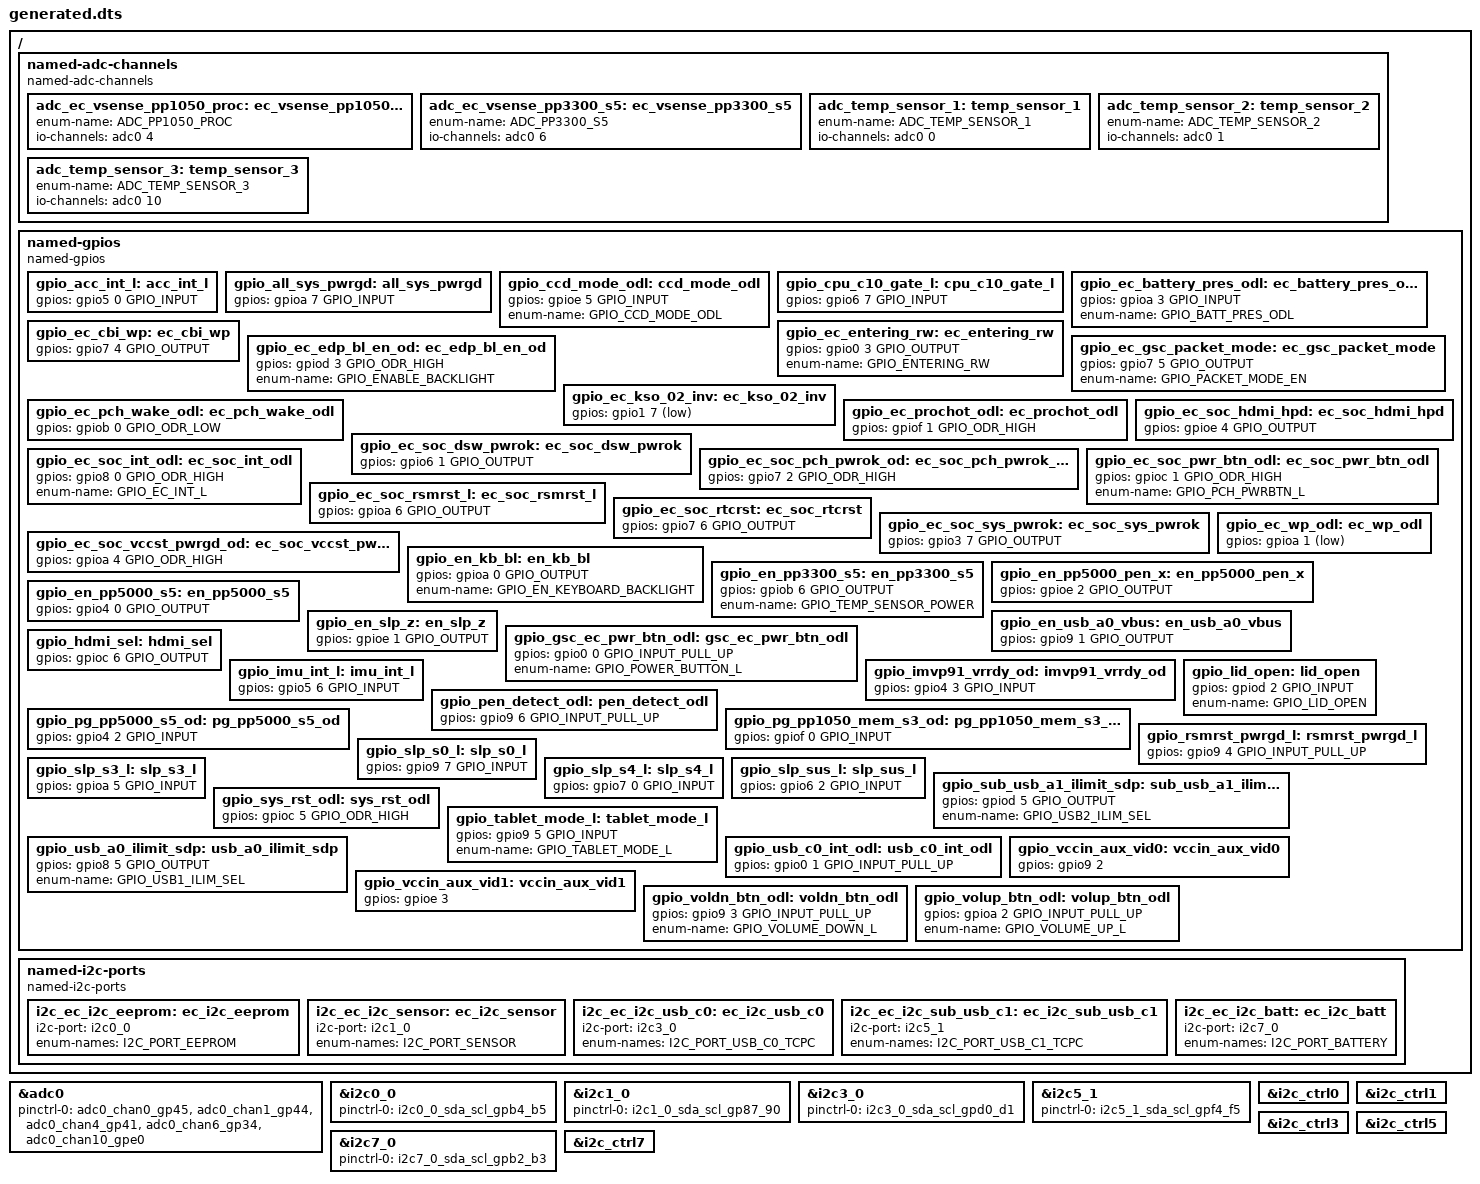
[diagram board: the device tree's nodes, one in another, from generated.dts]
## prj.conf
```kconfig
# Copyright 2022 The ChromiumOS Authors
# Use of this source code is governed by a BSD-style license that can be
# found in the LICENSE file.

CONFIG_BOARD_CRAASK=y
CONFIG_PLATFORM_EC_OCPC=y

# Sensor drivers
CONFIG_PLATFORM_EC_ACCELGYRO_LSM6DSO=y
CONFIG_PLATFORM_EC_ACCEL_BMA4XX=y
CONFIG_PLATFORM_EC_ACCELGYRO_BMI_COMM_I2C=y
CONFIG_PLATFORM_EC_ACCELGYRO_BMI3XX=y
CONFIG_PLATFORM_EC_DYNAMIC_MOTION_SENSOR_COUNT=y

CONFIG_PLATFORM_EC_BUTTONS_RUNTIME_CONFIG=y
```

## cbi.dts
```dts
/* Copyright 2022 The ChromiumOS Authors
 * Use of this source code is governed by a BSD-style license that can be
 * found in the LICENSE file.
 */

/ {
	/* Craask-specific fw_config fields. */
	nissa-fw-config {
		/*
		 * FW_CONFIG field to describe Lid sensor orientation.
		 */
		lid-inversion {
			enum-name = "FW_LID_INVERSION";
			start = <8>;
			size = <1>;

			/*
			 * 0: regular placement of the lid sensor
			 * 1: rotate 180' of xy plane.
			 */
			regular {
				compatible = "cros-ec,cbi-fw-config-value";
				enum-name = "FW_LID_REGULAR";
				value = <0>;
				default;
			};
			xy_rotate_180 {
				compatible = "cros-ec,cbi-fw-config-value";
				enum-name = "FW_LID_XY_ROT_180";
				value = <1>;
			};
		};
	};
	/* Craask-specific ssfc fields. */
	cbi-ssfc {
		compatible = "named-cbi-ssfc";
		/*
		 * SSFC bit0-1 was defined for AUDIO CODEC.
		 * 0: ALC5682I_VS
		 * 1: NAU8825
		 */
		audio_codec {
			enum-name = "AUDIO_CODEC";
			size = <2>;
		};
		/*
		 * SSFC field to identify LID motion sensor.
		 */
		lid-sensor {
			enum-name = "LID_SENSOR";
			size = <2>;

			lid_sensor_0: lis2dw12 {
				compatible = "named-cbi-ssfc-value";
				status = "okay";
				value = <0>;
				default;
			};
			lid_sensor_1: bma422 {
				compatible = "named-cbi-ssfc-value";
				status = "okay";
				value = <1>;
			};
		};
		/*
		 * SSFC field to identify BASE motion sensor.
		 */
		base-sensor {
			enum-name = "BASE_SENSOR";
			size = <2>;

			base_sensor_0: lsm6dso {
				compatible = "named-cbi-ssfc-value";
				status = "okay";
				value = <0>;
				default;
			};
			base_sensor_1: bmi323 {
				compatible = "named-cbi-ssfc-value";
				status = "okay";
				value = <1>;
			};
		};
	};
};
```

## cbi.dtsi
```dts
/* Copyright 2022 The ChromiumOS Authors
 * Use of this source code is governed by a BSD-style license that can be
 * found in the LICENSE file.
 */

/ {
	/* Craask-specific fw_config fields. */
	nissa-fw-config {
		/*
		 * FW_CONFIG field to describe Lid sensor orientation.
		 */
		lid-inversion {
			enum-name = "FW_LID_INVERSION";
			start = <8>;
			size = <1>;

			/*
			 * 0: regular placement of the lid sensor
			 * 1: rotate 180' of xy plane.
			 */
			regular {
				compatible = "cros-ec,cbi-fw-config-value";
				enum-name = "FW_LID_REGULAR";
				value = <0>;
				default;
			};
			xy_rotate_180 {
				compatible = "cros-ec,cbi-fw-config-value";
				enum-name = "FW_LID_XY_ROT_180";
				value = <1>;
			};
		};
		/*
		 * FW_CONFIG field to describe Clamshell/Convertible.
		 */
		form_factor {
			enum-name = "FORM_FACTOR";
			start = <9>;
			size = <1>;

			/*
			 * 0: convertible, 1: clamshell
			 */
			convertible {
				compatible = "cros-ec,cbi-fw-config-value";
				enum-name = "CONVERTIBLE";
				value = <0>;
			};
			clamshell {
				compatible = "cros-ec,cbi-fw-config-value";
				enum-name = "CLAMSHELL";
				value = <1>;
			};
		};
	};
	/* Craask-specific ssfc fields. */
	cbi-ssfc {
		compatible = "named-cbi-ssfc";
		/*
		 * SSFC bit0-1 was defined for AUDIO CODEC.
		 * 0: ALC5682I_VS
		 * 1: NAU8825
		 */
		audio_codec {
			enum-name = "AUDIO_CODEC";
			size = <2>;
		};
		/*
		 * SSFC field to identify LID motion sensor.
		 */
		lid-sensor {
			enum-name = "LID_SENSOR";
			size = <2>;

			lid_sensor_0: lis2dw12 {
				compatible = "named-cbi-ssfc-value";
				status = "okay";
				value = <0>;
				default;
			};
			lid_sensor_1: bma422 {
				compatible = "named-cbi-ssfc-value";
				status = "okay";
				value = <1>;
			};
		};
		/*
		 * SSFC field to identify BASE motion sensor.
		 */
		base-sensor {
			enum-name = "BASE_SENSOR";
			size = <2>;

			base_sensor_0: lsm6dso {
				compatible = "named-cbi-ssfc-value";
				status = "okay";
				value = <0>;
				default;
			};
			base_sensor_1: bmi323 {
				compatible = "named-cbi-ssfc-value";
				status = "okay";
				value = <1>;
			};
		};
	};
};
```

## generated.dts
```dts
/* Copyright 2022 The ChromiumOS Authors
 * Use of this source code is governed by a BSD-style license that can be
 * found in the LICENSE file.
 */

/ {

	named-adc-channels {
		compatible = "named-adc-channels";

		adc_ec_vsense_pp1050_proc: ec_vsense_pp1050_proc {
			enum-name = "ADC_PP1050_PROC";
			io-channels = <&adc0 4>;
		};
		adc_ec_vsense_pp3300_s5: ec_vsense_pp3300_s5 {
			enum-name = "ADC_PP3300_S5";
			io-channels = <&adc0 6>;
		};
		adc_temp_sensor_1: temp_sensor_1 {
			enum-name = "ADC_TEMP_SENSOR_1";
			io-channels = <&adc0 0>;
		};
		adc_temp_sensor_2: temp_sensor_2 {
			enum-name = "ADC_TEMP_SENSOR_2";
			io-channels = <&adc0 1>;
		};
		adc_temp_sensor_3: temp_sensor_3 {
			enum-name = "ADC_TEMP_SENSOR_3";
			io-channels = <&adc0 10>;
		};
	};

	named-gpios {
		compatible = "named-gpios";

		gpio_acc_int_l: acc_int_l {
			gpios = <&gpio5 0 GPIO_INPUT>;
		};
		gpio_all_sys_pwrgd: all_sys_pwrgd {
			gpios = <&gpioa 7 GPIO_INPUT>;
		};
		gpio_ccd_mode_odl: ccd_mode_odl {
			gpios = <&gpioe 5 GPIO_INPUT>;
			enum-name = "GPIO_CCD_MODE_ODL";
		};
		gpio_cpu_c10_gate_l: cpu_c10_gate_l {
			gpios = <&gpio6 7 GPIO_INPUT>;
		};
		gpio_ec_battery_pres_odl: ec_battery_pres_odl {
			gpios = <&gpioa 3 GPIO_INPUT>;
			enum-name = "GPIO_BATT_PRES_ODL";
		};
		gpio_ec_cbi_wp: ec_cbi_wp {
			gpios = <&gpio7 4 GPIO_OUTPUT>;
		};
		gpio_ec_edp_bl_en_od: ec_edp_bl_en_od {
			gpios = <&gpiod 3 GPIO_ODR_HIGH>;
			enum-name = "GPIO_ENABLE_BACKLIGHT";
		};
		gpio_ec_entering_rw: ec_entering_rw {
			gpios = <&gpio0 3 GPIO_OUTPUT>;
			enum-name = "GPIO_ENTERING_RW";
		};
		gpio_ec_gsc_packet_mode: ec_gsc_packet_mode {
			gpios = <&gpio7 5 GPIO_OUTPUT>;
			enum-name = "GPIO_PACKET_MODE_EN";
		};
		gpio_ec_kso_02_inv: ec_kso_02_inv {
			gpios = <&gpio1 7 (GPIO_OUTPUT | GPIO_ACTIVE_LOW)>;
		};
		gpio_ec_pch_wake_odl: ec_pch_wake_odl {
			gpios = <&gpiob 0 GPIO_ODR_LOW>;
		};
		gpio_ec_prochot_odl: ec_prochot_odl {
			gpios = <&gpiof 1 GPIO_ODR_HIGH>;
		};
		gpio_ec_soc_dsw_pwrok: ec_soc_dsw_pwrok {
			gpios = <&gpio6 1 GPIO_OUTPUT>;
		};
		gpio_ec_soc_hdmi_hpd: ec_soc_hdmi_hpd {
			gpios = <&gpioe 4 GPIO_OUTPUT>;
		};
		gpio_ec_soc_int_odl: ec_soc_int_odl {
			gpios = <&gpio8 0 GPIO_ODR_HIGH>;
			enum-name = "GPIO_EC_INT_L";
		};
		gpio_ec_soc_pch_pwrok_od: ec_soc_pch_pwrok_od {
			gpios = <&gpio7 2 GPIO_ODR_HIGH>;
		};
		gpio_ec_soc_pwr_btn_odl: ec_soc_pwr_btn_odl {
			gpios = <&gpioc 1 GPIO_ODR_HIGH>;
			enum-name = "GPIO_PCH_PWRBTN_L";
		};
		gpio_ec_soc_rsmrst_l: ec_soc_rsmrst_l {
			gpios = <&gpioa 6 GPIO_OUTPUT>;
		};
		gpio_ec_soc_rtcrst: ec_soc_rtcrst {
			gpios = <&gpio7 6 GPIO_OUTPUT>;
		};
		gpio_ec_soc_sys_pwrok: ec_soc_sys_pwrok {
			gpios = <&gpio3 7 GPIO_OUTPUT>;
		};
		gpio_ec_soc_vccst_pwrgd_od: ec_soc_vccst_pwrgd_od {
			gpios = <&gpioa 4 GPIO_ODR_HIGH>;
		};
		gpio_ec_wp_odl: ec_wp_odl {
			gpios = <&gpioa 1 (GPIO_INPUT | GPIO_ACTIVE_LOW)>;
		};
		gpio_en_kb_bl: en_kb_bl {
			gpios = <&gpioa 0 GPIO_OUTPUT>;
			enum-name = "GPIO_EN_KEYBOARD_BACKLIGHT";
		};
		gpio_en_pp3300_s5: en_pp3300_s5 {
			gpios = <&gpiob 6 GPIO_OUTPUT>;
			enum-name = "GPIO_TEMP_SENSOR_POWER";
		};
		gpio_en_pp5000_pen_x: en_pp5000_pen_x {
			gpios = <&gpioe 2 GPIO_OUTPUT>;
		};
		gpio_en_pp5000_s5: en_pp5000_s5 {
			gpios = <&gpio4 0 GPIO_OUTPUT>;
		};
		gpio_en_slp_z: en_slp_z {
			gpios = <&gpioe 1 GPIO_OUTPUT>;
		};
		gpio_en_usb_a0_vbus: en_usb_a0_vbus {
			gpios = <&gpio9 1 GPIO_OUTPUT>;
		};
		gpio_gsc_ec_pwr_btn_odl: gsc_ec_pwr_btn_odl {
			gpios = <&gpio0 0 GPIO_INPUT_PULL_UP>;
			enum-name = "GPIO_POWER_BUTTON_L";
		};
		gpio_hdmi_sel: hdmi_sel {
			gpios = <&gpioc 6 GPIO_OUTPUT>;
		};
		gpio_imu_int_l: imu_int_l {
			gpios = <&gpio5 6 GPIO_INPUT>;
		};
		gpio_imvp91_vrrdy_od: imvp91_vrrdy_od {
			gpios = <&gpio4 3 GPIO_INPUT>;
		};
		gpio_lid_open: lid_open {
			gpios = <&gpiod 2 GPIO_INPUT>;
			enum-name = "GPIO_LID_OPEN";
		};
		gpio_pen_detect_odl: pen_detect_odl {
			gpios = <&gpio9 6 GPIO_INPUT_PULL_UP>;
		};
		gpio_pg_pp1050_mem_s3_od: pg_pp1050_mem_s3_od {
			gpios = <&gpiof 0 GPIO_INPUT>;
		};
		gpio_pg_pp5000_s5_od: pg_pp5000_s5_od {
			gpios = <&gpio4 2 GPIO_INPUT>;
		};
		gpio_rsmrst_pwrgd_l: rsmrst_pwrgd_l {
			gpios = <&gpio9 4 GPIO_INPUT_PULL_UP>;
		};
		gpio_slp_s0_l: slp_s0_l {
			gpios = <&gpio9 7 GPIO_INPUT>;
		};
		gpio_slp_s3_l: slp_s3_l {
			gpios = <&gpioa 5 GPIO_INPUT>;
		};
		gpio_slp_s4_l: slp_s4_l {
			gpios = <&gpio7 0 GPIO_INPUT>;
		};
		gpio_slp_sus_l: slp_sus_l {
			gpios = <&gpio6 2 GPIO_INPUT>;
		};
		gpio_sub_usb_a1_ilimit_sdp: sub_usb_a1_ilimit_sdp {
			gpios = <&gpiod 5 GPIO_OUTPUT>;
			enum-name = "GPIO_USB2_ILIM_SEL";
		};
		gpio_sys_rst_odl: sys_rst_odl {
			gpios = <&gpioc 5 GPIO_ODR_HIGH>;
		};
		gpio_tablet_mode_l: tablet_mode_l {
			gpios = <&gpio9 5 GPIO_INPUT>;
			enum-name = "GPIO_TABLET_MODE_L";
		};
		gpio_usb_a0_ilimit_sdp: usb_a0_ilimit_sdp {
			gpios = <&gpio8 5 GPIO_OUTPUT>;
			enum-name = "GPIO_USB1_ILIM_SEL";
		};
		gpio_usb_c0_int_odl: usb_c0_int_odl {
			gpios = <&gpio0 1 GPIO_INPUT_PULL_UP>;
		};
		gpio_vccin_aux_vid0: vccin_aux_vid0 {
			gpios = <&gpio9 2 (GPIO_INPUT | GPIO_VOLTAGE_1P8)>;
		};
		gpio_vccin_aux_vid1: vccin_aux_vid1 {
			gpios = <&gpioe 3 (GPIO_INPUT | GPIO_VOLTAGE_1P8)>;
		};
		gpio_voldn_btn_odl: voldn_btn_odl {
			gpios = <&gpio9 3 GPIO_INPUT_PULL_UP>;
			enum-name = "GPIO_VOLUME_DOWN_L";
		};
		gpio_volup_btn_odl: volup_btn_odl {
			gpios = <&gpioa 2 GPIO_INPUT_PULL_UP>;
			enum-name = "GPIO_VOLUME_UP_L";
		};
	};

	named-i2c-ports {
		compatible = "named-i2c-ports";

		i2c_ec_i2c_eeprom: ec_i2c_eeprom {
			i2c-port = <&i2c0_0>;
			enum-names = "I2C_PORT_EEPROM";
		};
		i2c_ec_i2c_sensor: ec_i2c_sensor {
			i2c-port = <&i2c1_0>;
			enum-names = "I2C_PORT_SENSOR";
		};
		i2c_ec_i2c_usb_c0: ec_i2c_usb_c0 {
			i2c-port = <&i2c3_0>;
			enum-names = "I2C_PORT_USB_C0_TCPC";
		};
		i2c_ec_i2c_sub_usb_c1: ec_i2c_sub_usb_c1 {
			i2c-port = <&i2c5_1>;
			enum-names = "I2C_PORT_USB_C1_TCPC";
		};
		i2c_ec_i2c_batt: ec_i2c_batt {
			i2c-port = <&i2c7_0>;
			enum-names = "I2C_PORT_BATTERY";
		};
	};
};

&adc0 {
	status = "okay";
	pinctrl-0 = <&adc0_chan0_gp45
		     &adc0_chan1_gp44
		     &adc0_chan4_gp41
		     &adc0_chan6_gp34
		     &adc0_chan10_gpe0>;
	pinctrl-names = "default";
};

&i2c0_0 {
	status = "okay";
	pinctrl-0 = <&i2c0_0_sda_scl_gpb4_b5>;
	pinctrl-names = "default";
};

&i2c1_0 {
	status = "okay";
	pinctrl-0 = <&i2c1_0_sda_scl_gp87_90>;
	pinctrl-names = "default";
};

&i2c3_0 {
	status = "okay";
	pinctrl-0 = <&i2c3_0_sda_scl_gpd0_d1>;
	pinctrl-names = "default";
};

&i2c5_1 {
	status = "okay";
	pinctrl-0 = <&i2c5_1_sda_scl_gpf4_f5>;
	pinctrl-names = "default";
};

&i2c7_0 {
	status = "okay";
	pinctrl-0 = <&i2c7_0_sda_scl_gpb2_b3>;
	pinctrl-names = "default";
};

&i2c_ctrl0 {
	status = "okay";
};

&i2c_ctrl1 {
	status = "okay";
};

&i2c_ctrl3 {
	status = "okay";
};

&i2c_ctrl5 {
	status = "okay";
};

&i2c_ctrl7 {
	status = "okay";
};
```

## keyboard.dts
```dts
/* Copyright 2022 The Chromium OS Authors. All rights reserved.
 * Use of this source code is governed by a BSD-style license that can be
 * found in the LICENSE file.
 */

&cros_kb_raw {
	status = "okay";
	/* No KSO2 (it's inverted and implemented by GPIO) */
	pinctrl-0 = <
		&ksi0_gp31
		&ksi1_gp30
		&ksi2_gp27
		&ksi3_gp26
		&ksi4_gp25
		&ksi5_gp24
		&ksi6_gp23
		&ksi7_gp22
		&kso00_gp21
		&kso01_gp20
		&kso03_gp16
		&kso04_gp15
		&kso05_gp14
		&kso06_gp13
		&kso07_gp12
		&kso08_gp11
		&kso09_gp10
		&kso10_gp07
		&kso11_gp06
		&kso12_gp05
	>;
	pinctrl-names = "default";
};
```

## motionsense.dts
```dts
/* Copyright 2022 The Chromium OS Authors. All rights reserved.
 * Use of this source code is governed by a BSD-style license that can be
 * found in the LICENSE file.
 */

#include <dt-bindings/motionsense/utils.h>


/ {
	aliases {
		/*
		 * Interrupt bindings for sensor devices.
		 */
		lsm6dso-int = &base_accel;
		lis2dw12-int = &lid_accel;
		bmi3xx-int = &base_accel;
	};

	/*
	 * Declare mutexes used by sensor drivers.
	 * A mutex node is used to create an instance of mutex_t.
	 * A mutex node is referenced by a sensor node if the
	 * corresponding sensor driver needs to use the
	 * instance of the mutex.
	 */
	motionsense-mutex {
		compatible = "cros-ec,motionsense-mutex";
		lid_mutex: lis2dw12-mutex {
		};

		lid_mutex_bma422: bma422-mutex {
		};

		base_mutex: base-mutex {
		};

		base_mutex_bmi323: bmi323-mutex {
		};
	};

	/* Rotation matrix used by drivers. */
	motionsense-rotation-ref {
		compatible = "cros-ec,motionsense-rotation-ref";
		lid_rot_ref: lid-rotation-ref {
			mat33 = <(-1) 0 0
				 0 1 0
				 0 0 (-1)>;
		};

		base_rot_ref: base-rotation-ref {
			mat33 = <1 0 0
				 0 (-1) 0
				 0 0 (-1)>;
		};

		base_rot_ver1: base-rotation-ver1 {
			mat33 = <(-1) 0 0
				 0 (-1) 0
				 0 0 1>;
		};

		lid_rot_bma422: lid-rotation-bma {
			mat33 = <1 0 0
				 0 (-1) 0
				 0 0 (-1)>;
		};

		base_rot_bmi323: base-rotation-bmi323 {
			mat33 = <1 0 0
				 0 (-1) 0
				 0 0 (-1)>;
		};
	};

	/*
	 * Driver specific data. A driver-specific data can be shared with
	 * different motion sensors while they are using the same driver.
	 *
	 * If a node's compatible starts with "cros-ec,accelgyro-", it is for
	 * a common structure defined in accelgyro.h.
	 * e.g) compatible = "cros-ec,accelgyro-als-drv-data" is for
	 * "struct als_drv_data_t" in accelgyro.h
	 */
	motionsense-sensor-data {
		lsm6dso_accel_data: lsm6dso-accel-drv-data {
			compatible = "cros-ec,drvdata-lsm6dso";
			status = "okay";
		};

		lsm6dso_gyro_data: lsm6dso-gyro-drv-data {
			compatible = "cros-ec,drvdata-lsm6dso";
			status = "okay";
		};

		lis2dw12_data: lis2dw12-drv-data {
			compatible = "cros-ec,drvdata-lis2dw12";
			status = "okay";
		};

		bma422_data: bma4xx-drv-data {
			compatible = "cros-ec,drvdata-bma4xx";
			status = "okay";
		};

		bmi323_data: bmi323-drv-data {
			compatible = "cros-ec,drvdata-bmi3xx";
			status = "okay";
		};
	};

	/*
	 * List of motion sensors that creates motion_sensors array.
	 * The nodelabel "lid_accel" and "base_accel" are used to indicate
	 * motion sensor IDs for lid angle calculation.
	 * TODO(b/238139272): The first entries of the array must be
	 * accelerometers,then gyroscope. Fix this dependency in the DTS
	 * processing which makes the devicetree entries independent.
	 */
	motionsense-sensor {
		lid_accel: lid-accel {
			compatible = "cros-ec,lis2dw12";
			status = "okay";

			active-mask = "SENSOR_ACTIVE_S0_S3";
			location = "MOTIONSENSE_LOC_LID";
			mutex = <&lid_mutex>;
			port = <&i2c_ec_i2c_sensor>;
			rot-standard-ref = <&lid_rot_ref>;
			default-range = <2>;
			drv-data = <&lis2dw12_data>;
			i2c-spi-addr-flags = "LIS2DWL_ADDR0_FLAGS";
			configs {
				compatible =
					"cros-ec,motionsense-sensor-config";
				ec-s0 {
					odr = <(10000 | ROUND_UP_FLAG)>;
				};
				ec-s3 {
					odr = <(10000 | ROUND_UP_FLAG)>;
				};
			};
		};

		base_accel: base-accel {
			compatible = "cros-ec,lsm6dso-accel";
			status = "okay";

			active-mask = "SENSOR_ACTIVE_S0_S3";
			location = "MOTIONSENSE_LOC_BASE";
			mutex = <&base_mutex>;
			port = <&i2c_ec_i2c_sensor>;
			rot-standard-ref = <&base_rot_ref>;
			drv-data = <&lsm6dso_accel_data>;
			configs {
				compatible =
					"cros-ec,motionsense-sensor-config";
				ec-s0 {
					odr = <(10000 | ROUND_UP_FLAG)>;
				};
				ec-s3 {
					odr = <(10000 | ROUND_UP_FLAG)>;
				};
			};
		};

		base_gyro: base-gyro {
			compatible = "cros-ec,lsm6dso-gyro";
			status = "okay";

			active-mask = "SENSOR_ACTIVE_S0_S3";
			location = "MOTIONSENSE_LOC_BASE";
			mutex = <&base_mutex>;
			port = <&i2c_ec_i2c_sensor>;
			rot-standard-ref = <&base_rot_ref>;
			default-range = <(1000 | ROUND_UP_FLAG)>; /* dps */
			drv-data = <&lsm6dso_gyro_data>;
		};
	};

	motionsense-sensor-alt {
		alt_lid_accel: alt-lid-accel {
			compatible = "cros-ec,bma4xx";
			status = "okay";

			active-mask = "SENSOR_ACTIVE_S0_S3";
			location = "MOTIONSENSE_LOC_LID";
			mutex = <&lid_mutex_bma422>;
			port = <&i2c_ec_i2c_sensor>;
			rot-standard-ref = <&lid_rot_bma422>;
			default-range = <2>;
			drv-data = <&bma422_data>;
			i2c-spi-addr-flags = "BMA4_I2C_ADDR_PRIMARY";
			alternate-for = <&lid_accel>;
			alternate-ssfc-indicator = <&lid_sensor_1>;
			configs {
				compatible =
					"cros-ec,motionsense-sensor-config";
				ec-s0 {
					odr = <(10000 | ROUND_UP_FLAG)>;
				};
				ec-s3 {
					odr = <(10000 | ROUND_UP_FLAG)>;
				};
			};
		};

		alt_base_accel: alt-base-accel {
			compatible = "cros-ec,bmi3xx-accel";
			status = "okay";

			active-mask = "SENSOR_ACTIVE_S0_S3";
			location = "MOTIONSENSE_LOC_BASE";
			mutex = <&base_mutex_bmi323>;
			port = <&i2c_ec_i2c_sensor>;
			rot-standard-ref = <&base_rot_bmi323>;
			drv-data = <&bmi323_data>;
			alternate-for = <&base_accel>;
			alternate-ssfc-indicator = <&base_sensor_1>;
			configs {
				compatible =
					"cros-ec,motionsense-sensor-config";
				ec-s0 {
					odr = <(10000 | ROUND_UP_FLAG)>;
				};
				ec-s3 {
					odr = <(10000 | ROUND_UP_FLAG)>;
				};
			};
		};

		alt_base_gyro: alt-base-gyro {
			compatible = "cros-ec,bmi3xx-gyro";
			status = "okay";

			active-mask = "SENSOR_ACTIVE_S0_S3";
			location = "MOTIONSENSE_LOC_BASE";
			mutex = <&base_mutex_bmi323>;
			port = <&i2c_ec_i2c_sensor>;
			rot-standard-ref = <&base_rot_bmi323>;
			drv-data = <&bmi323_data>;
			alternate-for = <&base_gyro>;
			alternate-ssfc-indicator = <&base_sensor_1>;
		};
	};

	motionsense-sensor-info {
		compatible = "cros-ec,motionsense-sensor-info";

		/*
		 * list of GPIO interrupts that have to
		 * be enabled at initial stage
		 */
		sensor-irqs = <&int_imu>;
		/* list of sensors in force mode */
		accel-force-mode-sensors = <&lid_accel>;
	};
};
```

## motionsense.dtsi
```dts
/* Copyright 2022 The ChromiumOS Authors
 * Use of this source code is governed by a BSD-style license that can be
 * found in the LICENSE file.
 */

#include <dt-bindings/motionsense/utils.h>


/ {
	aliases {
		/*
		 * Interrupt bindings for sensor devices.
		 */
		lsm6dso-int = &base_accel;
		lis2dw12-int = &lid_accel;
		bmi3xx-int = &base_accel;
	};

	/*
	 * Declare mutexes used by sensor drivers.
	 * A mutex node is used to create an instance of mutex_t.
	 * A mutex node is referenced by a sensor node if the
	 * corresponding sensor driver needs to use the
	 * instance of the mutex.
	 */
	motionsense-mutex {
		compatible = "cros-ec,motionsense-mutex";
		lid_mutex: lis2dw12-mutex {
		};

		lid_mutex_bma422: bma422-mutex {
		};

		base_mutex: base-mutex {
		};

		base_mutex_bmi323: bmi323-mutex {
		};
	};

	/* Rotation matrix used by drivers. */
	motionsense-rotation-ref {
		compatible = "cros-ec,motionsense-rotation-ref";
		lid_rot_ref: lid-rotation-ref {
			mat33 = <(-1) 0 0
				 0 1 0
				 0 0 (-1)>;
		};

		base_rot_ref: base-rotation-ref {
			mat33 = <1 0 0
				 0 (-1) 0
				 0 0 (-1)>;
		};

		base_rot_ver1: base-rotation-ver1 {
			mat33 = <(-1) 0 0
				 0 (-1) 0
				 0 0 1>;
		};

		lid_rot_bma422: lid-rotation-bma {
			mat33 = <1 0 0
				 0 (-1) 0
				 0 0 (-1)>;
		};

		base_rot_bmi323: base-rotation-bmi323 {
			mat33 = <1 0 0
				 0 (-1) 0
				 0 0 (-1)>;
		};
	};

	/*
	 * Driver specific data. A driver-specific data can be shared with
	 * different motion sensors while they are using the same driver.
	 *
	 * If a node's compatible starts with "cros-ec,accelgyro-", it is for
	 * a common structure defined in accelgyro.h.
	 * e.g) compatible = "cros-ec,accelgyro-als-drv-data" is for
	 * "struct als_drv_data_t" in accelgyro.h
	 */
	motionsense-sensor-data {
		lsm6dso_accel_data: lsm6dso-accel-drv-data {
			compatible = "cros-ec,drvdata-lsm6dso";
			status = "okay";
		};

		lsm6dso_gyro_data: lsm6dso-gyro-drv-data {
			compatible = "cros-ec,drvdata-lsm6dso";
			status = "okay";
		};

		lis2dw12_data: lis2dw12-drv-data {
			compatible = "cros-ec,drvdata-lis2dw12";
			status = "okay";
		};

		bma422_data: bma4xx-drv-data {
			compatible = "cros-ec,drvdata-bma4xx";
			status = "okay";
		};

		bmi323_data: bmi323-drv-data {
			compatible = "cros-ec,drvdata-bmi3xx";
			status = "okay";
		};
	};

	/*
	 * List of motion sensors that creates motion_sensors array.
	 * The nodelabel "lid_accel" and "base_accel" are used to indicate
	 * motion sensor IDs for lid angle calculation.
	 * TODO(b/238139272): The first entries of the array must be
	 * accelerometers,then gyroscope. Fix this dependency in the DTS
	 * processing which makes the devicetree entries independent.
	 */
	motionsense-sensor {
		lid_accel: lid-accel {
			compatible = "cros-ec,lis2dw12";
			status = "okay";

			active-mask = "SENSOR_ACTIVE_S0_S3";
			location = "MOTIONSENSE_LOC_LID";
			mutex = <&lid_mutex>;
			port = <&i2c_ec_i2c_sensor>;
			rot-standard-ref = <&lid_rot_ref>;
			default-range = <2>;
			drv-data = <&lis2dw12_data>;
			i2c-spi-addr-flags = "LIS2DWL_ADDR0_FLAGS";
			configs {
				compatible =
					"cros-ec,motionsense-sensor-config";
				ec-s0 {
					odr = <(10000 | ROUND_UP_FLAG)>;
				};
				ec-s3 {
					odr = <(10000 | ROUND_UP_FLAG)>;
				};
			};
		};

		base_accel: base-accel {
			compatible = "cros-ec,lsm6dso-accel";
			status = "okay";

			active-mask = "SENSOR_ACTIVE_S0_S3";
			location = "MOTIONSENSE_LOC_BASE";
			mutex = <&base_mutex>;
			port = <&i2c_ec_i2c_sensor>;
			rot-standard-ref = <&base_rot_ref>;
			drv-data = <&lsm6dso_accel_data>;
			configs {
				compatible =
					"cros-ec,motionsense-sensor-config";
				ec-s0 {
					odr = <(10000 | ROUND_UP_FLAG)>;
				};
				ec-s3 {
					odr = <(10000 | ROUND_UP_FLAG)>;
				};
			};
		};

		base_gyro: base-gyro {
			compatible = "cros-ec,lsm6dso-gyro";
			status = "okay";

			active-mask = "SENSOR_ACTIVE_S0_S3";
			location = "MOTIONSENSE_LOC_BASE";
			mutex = <&base_mutex>;
			port = <&i2c_ec_i2c_sensor>;
			rot-standard-ref = <&base_rot_ref>;
			default-range = <(1000 | ROUND_UP_FLAG)>; /* dps */
			drv-data = <&lsm6dso_gyro_data>;
		};
	};

	motionsense-sensor-alt {
		alt_lid_accel: alt-lid-accel {
			compatible = "cros-ec,bma4xx";
			status = "okay";

			active-mask = "SENSOR_ACTIVE_S0_S3";
			location = "MOTIONSENSE_LOC_LID";
			mutex = <&lid_mutex_bma422>;
			port = <&i2c_ec_i2c_sensor>;
			rot-standard-ref = <&lid_rot_bma422>;
			default-range = <2>;
			drv-data = <&bma422_data>;
			i2c-spi-addr-flags = "BMA4_I2C_ADDR_PRIMARY";
			alternate-for = <&lid_accel>;
			alternate-ssfc-indicator = <&lid_sensor_1>;
			configs {
				compatible =
					"cros-ec,motionsense-sensor-config";
				ec-s0 {
					odr = <(10000 | ROUND_UP_FLAG)>;
				};
				ec-s3 {
					odr = <(10000 | ROUND_UP_FLAG)>;
				};
			};
		};

		alt_base_accel: alt-base-accel {
			compatible = "cros-ec,bmi3xx-accel";
			status = "okay";

			active-mask = "SENSOR_ACTIVE_S0_S3";
			location = "MOTIONSENSE_LOC_BASE";
			mutex = <&base_mutex_bmi323>;
			port = <&i2c_ec_i2c_sensor>;
			rot-standard-ref = <&base_rot_bmi323>;
			drv-data = <&bmi323_data>;
			alternate-for = <&base_accel>;
			alternate-ssfc-indicator = <&base_sensor_1>;
			configs {
				compatible =
					"cros-ec,motionsense-sensor-config";
				ec-s0 {
					odr = <(10000 | ROUND_UP_FLAG)>;
				};
				ec-s3 {
					odr = <(10000 | ROUND_UP_FLAG)>;
				};
			};
		};

		alt_base_gyro: alt-base-gyro {
			compatible = "cros-ec,bmi3xx-gyro";
			status = "okay";

			active-mask = "SENSOR_ACTIVE_S0_S3";
			location = "MOTIONSENSE_LOC_BASE";
			mutex = <&base_mutex_bmi323>;
			port = <&i2c_ec_i2c_sensor>;
			rot-standard-ref = <&base_rot_bmi323>;
			drv-data = <&bmi323_data>;
			alternate-for = <&base_gyro>;
			alternate-ssfc-indicator = <&base_sensor_1>;
		};
	};

	motionsense-sensor-info {
		compatible = "cros-ec,motionsense-sensor-info";

		/*
		 * list of GPIO interrupts that have to
		 * be enabled at initial stage
		 */
		sensor-irqs = <&int_imu>;
		/* list of sensors in force mode */
		accel-force-mode-sensors = <&lid_accel>;
	};
};
```

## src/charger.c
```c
/* Copyright 2022 The Chromium OS Authors. All rights reserved.
 * Use of this source code is governed by a BSD-style license that can be
 * found in the LICENSE file.
 */

#include <zephyr/logging/log.h>

#include "battery.h"
#include "charger.h"
#include "charger/isl923x_public.h"
#include "console.h"
#include "extpower.h"
#include "usb_pd.h"
#include "nissa_common.h"

LOG_MODULE_DECLARE(nissa, CONFIG_NISSA_LOG_LEVEL);

int extpower_is_present(void)
{
	int port;
	int rv;
	bool acok;

	for (port = 0; port < board_get_usb_pd_port_count(); port++) {
		rv = raa489000_is_acok(port, &acok);
		if ((rv == EC_SUCCESS) && acok)
			return 1;
	}

	return 0;
}

/*
 * Craask does not have a GPIO indicating whether extpower is present,
 * so detect using the charger(s).
 */
__override void board_check_extpower(void)
{
	static int last_extpower_present;
	int extpower_present = extpower_is_present();

	if (last_extpower_present ^ extpower_present)
		extpower_handle_update(extpower_present);

	last_extpower_present = extpower_present;
}

__override void board_hibernate(void)
{
	/* Shut down the chargers */
	if (board_get_usb_pd_port_count() == 2)
		raa489000_hibernate(CHARGER_SECONDARY, true);
	raa489000_hibernate(CHARGER_PRIMARY, true);
	LOG_INF("Charger(s) hibernated");
	cflush();
}
```

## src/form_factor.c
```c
/* Copyright 2022 The ChromiumOS Authors
 * Use of this source code is governed by a BSD-style license that can be
 * found in the LICENSE file.
 */

#include <zephyr/devicetree.h>
#include <zephyr/logging/log.h>

#include "accelgyro.h"
#include "button.h"
#include "cros_board_info.h"
#include "cros_cbi.h"
#include "driver/accelgyro_bmi323.h"
#include "driver/accelgyro_lsm6dso.h"
#include "gpio/gpio_int.h"
#include "hooks.h"
#include "motionsense_sensors.h"
#include "motion_sense.h"
#include "tablet_mode.h"

#include "nissa_common.h"

LOG_MODULE_DECLARE(nissa, CONFIG_NISSA_LOG_LEVEL);

/*
 * Mainboard orientation support.
 */

#define LIS_ALT_MAT SENSOR_ROT_STD_REF_NAME(DT_NODELABEL(lid_rot_bma422))
#define BMA_ALT_MAT SENSOR_ROT_STD_REF_NAME(DT_NODELABEL(lid_rot_ref))
#define ALT_MAT SENSOR_ROT_STD_REF_NAME(DT_NODELABEL(base_rot_ver1))
#define LID_SENSOR SENSOR_ID(DT_NODELABEL(lid_accel))
#define BASE_SENSOR SENSOR_ID(DT_NODELABEL(base_accel))
#define BASE_GYRO SENSOR_ID(DT_NODELABEL(base_gyro))
#define ALT_LID_S SENSOR_ID(DT_NODELABEL(alt_lid_accel))

static bool use_alt_sensor;

void motion_interrupt(enum gpio_signal signal)
{
	if (use_alt_sensor)
		bmi3xx_interrupt(signal);
	else
		lsm6dso_interrupt(signal);
}

static void form_factor_init(void)
{
	int ret;
	uint32_t val;
	enum nissa_sub_board_type sb = nissa_get_sb_type();

	ret = cbi_get_board_version(&val);
	if (ret != EC_SUCCESS) {
		LOG_ERR("Error retrieving CBI BOARD_VER.");
		return;
	}
	/*
	 * The volume up/down button are exchanged on ver3 USB
	 * sub board.
	 *
	 * LTE:
	 *   volup -> gpioa2, voldn -> gpio93
	 * USB:
	 *   volup -> gpio93, voldn -> gpioa2
	 */
	if (val == 3 && sb == NISSA_SB_C_A) {
		LOG_INF("Volume up/down btn exchanged on ver3 USB sku");
		buttons[BUTTON_VOLUME_UP].gpio = GPIO_VOLUME_DOWN_L;
		buttons[BUTTON_VOLUME_DOWN].gpio = GPIO_VOLUME_UP_L;
	}

	/*
	 * If the board version is 1
	 * use ver1 rotation matrix.
	 */
	if (val == 1) {
		LOG_INF("Switching to ver1 base");
		motion_sensors[BASE_SENSOR].rot_standard_ref = &ALT_MAT;
		motion_sensors[BASE_GYRO].rot_standard_ref = &ALT_MAT;
	}

	/*
	 * If the firmware config indicates
	 * an craaskbowl form factor, use the alternative
	 * rotation matrix.
	 */
	ret = cros_cbi_get_fw_config(FW_LID_INVERSION, &val);
	if (ret != 0) {
		LOG_ERR("Error retrieving CBI FW_CONFIG field %d",
			FW_LID_INVERSION);
		return;
	}
	if (val == FW_LID_XY_ROT_180) {
		LOG_INF("Lid sensor placement rotate 180 on xy plane");
		motion_sensors[LID_SENSOR].rot_standard_ref = &LIS_ALT_MAT;
		motion_sensors_alt[ALT_LID_S].rot_standard_ref = &BMA_ALT_MAT;
	}

	/* check which base sensor is used for motion_interrupt */
	use_alt_sensor = cros_cbi_ssfc_check_match(
		CBI_SSFC_VALUE_ID(DT_NODELABEL(base_sensor_1)));

	motion_sensors_check_ssfc();

	/* Check if it's clamshell or convertible */
	ret = cros_cbi_get_fw_config(FORM_FACTOR, &val);
	if (ret != 0) {
		LOG_ERR("Error retrieving CBI FW_CONFIG field %d", FORM_FACTOR);
		return;
	}
	if (val == CLAMSHELL) {
		LOG_INF("Clamshell: disable motionsense function.");
		motion_sensor_count = 0;
		gmr_tablet_switch_disable();
		gpio_disable_dt_interrupt(GPIO_INT_FROM_NODELABEL(int_imu));
		gpio_pin_configure_dt(GPIO_DT_FROM_NODELABEL(gpio_imu_int_l),
				      GPIO_DISCONNECTED);
	}
}
DECLARE_HOOK(HOOK_INIT, form_factor_init, HOOK_PRIO_POST_I2C);
```

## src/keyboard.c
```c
/* Copyright 2022 The ChromiumOS Authors
 * Use of this source code is governed by a BSD-style license that can be
 * found in the LICENSE file.
 */

#include "ec_commands.h"

static const struct ec_response_keybd_config craask_kb = {
	.num_top_row_keys = 10,
	.action_keys = {
		TK_BACK,		/* T1 */
		TK_REFRESH,		/* T2 */
		TK_FULLSCREEN,		/* T3 */
		TK_OVERVIEW,		/* T4 */
		TK_SNAPSHOT,		/* T5 */
		TK_BRIGHTNESS_DOWN,	/* T6 */
		TK_BRIGHTNESS_UP,	/* T7 */
		TK_VOL_MUTE,		/* T8 */
		TK_VOL_DOWN,		/* T9 */
		TK_VOL_UP,		/* T10 */
	},
	.capabilities = KEYBD_CAP_SCRNLOCK_KEY,
};

__override const struct ec_response_keybd_config *
board_vivaldi_keybd_config(void)
{
	return &craask_kb;
}
```

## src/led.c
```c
/* Copyright 2022 The ChromiumOS Authors.
 * Use of this source code is governed by a BSD-style license that can be
 * found in the LICENSE file.
 *
 * Battery LED control for nissa
 */
#include "common.h"
#include "ec_commands.h"
#include "led_common.h"
#include "led_onoff_states.h"
#include "led_pwm.h"

__override const int led_charge_lvl_1 = 5;
__override const int led_charge_lvl_2 = 97;
__override struct led_descriptor
	led_bat_state_table[LED_NUM_STATES][LED_NUM_PHASES] = {
		[STATE_CHARGING_LVL_1] = { { EC_LED_COLOR_AMBER,
					     LED_INDEFINITE } },
		[STATE_CHARGING_LVL_2] = { { EC_LED_COLOR_AMBER,
					     LED_INDEFINITE } },
		[STATE_CHARGING_FULL_CHARGE] = { { EC_LED_COLOR_BLUE,
						   LED_INDEFINITE } },
		[STATE_DISCHARGE_S0] = { { EC_LED_COLOR_BLUE,
					   LED_INDEFINITE } },
		[STATE_DISCHARGE_S0_BAT_LOW] = { { EC_LED_COLOR_AMBER,
						   LED_INDEFINITE } },
		[STATE_DISCHARGE_S3] = { { EC_LED_COLOR_AMBER,
					   1 * LED_ONE_SEC },
					 { LED_OFF, 3 * LED_ONE_SEC } },
		[STATE_DISCHARGE_S5] = { { LED_OFF, LED_INDEFINITE } },
		[STATE_BATTERY_ERROR] = { { EC_LED_COLOR_AMBER,
					    1 * LED_ONE_SEC },
					  { LED_OFF, 1 * LED_ONE_SEC } },
		[STATE_FACTORY_TEST] = { { EC_LED_COLOR_AMBER,
					   2 * LED_ONE_SEC },
					 { EC_LED_COLOR_BLUE,
					   2 * LED_ONE_SEC } },
	};

__override void led_set_color_battery(enum ec_led_colors color)
{
	switch (color) {
	case EC_LED_COLOR_RED:
		set_pwm_led_color(EC_LED_ID_BATTERY_LED, EC_LED_COLOR_RED);
		break;
	case EC_LED_COLOR_BLUE:
		set_pwm_led_color(EC_LED_ID_BATTERY_LED, EC_LED_COLOR_BLUE);
		break;
	case EC_LED_COLOR_AMBER:
		set_pwm_led_color(EC_LED_ID_BATTERY_LED, EC_LED_COLOR_AMBER);
		break;
	default: /* LED_OFF and other unsupported colors */
		set_pwm_led_color(EC_LED_ID_BATTERY_LED, -1);
		break;
	}
}
```
